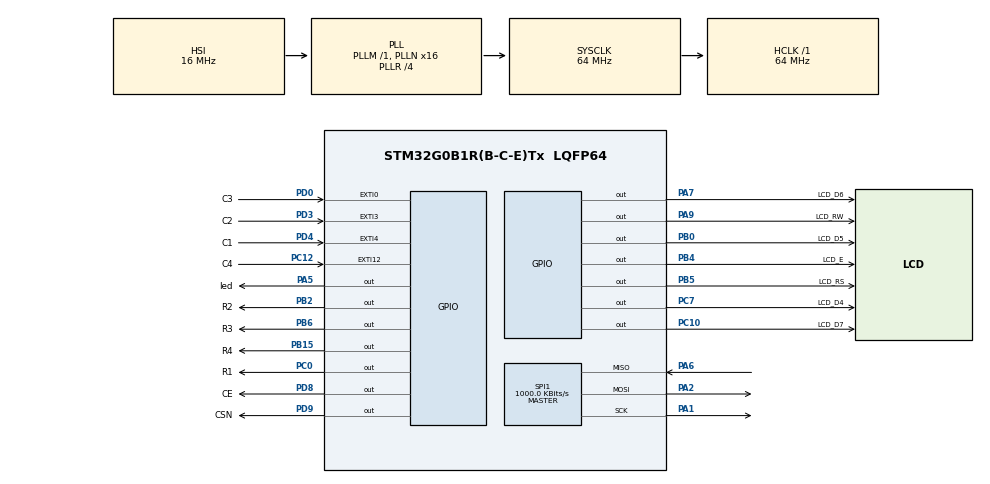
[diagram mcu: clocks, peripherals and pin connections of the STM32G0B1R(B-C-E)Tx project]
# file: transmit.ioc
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Mcu.Family=STM32G0
Mcu.Name=STM32G0B1R(B-C-E)Tx
Mcu.Package=LQFP64
NVIC.EXTI0_1_IRQn=true\:0\:0\:false\:false\:true\:true\:true
NVIC.EXTI2_3_IRQn=true\:0\:0\:false\:false\:true\:true\:true
NVIC.EXTI4_15_IRQn=true\:0\:0\:false\:false\:true\:true\:true
NVIC.SPI1_IRQn=true\:0\:0\:false\:false\:true\:true\:true
NVIC.TIM1_BRK_UP_TRG_COM_IRQn=true\:0\:0\:false\:false\:true\:true\:true
NVIC.TIM1_CC_IRQn=true\:0\:0\:false\:false\:true\:true\:true
PA1.Mode=Full_Duplex_Master
PA1.Signal=SPI1_SCK
PA13.Mode=Serial_Wire
PA13.Signal=SYS_SWDIO
PA14-BOOT0.Mode=Serial_Wire
PA14-BOOT0.Signal=SYS_SWCLK
PA2.Mode=Full_Duplex_Master
PA2.Signal=SPI1_MOSI
PA5.GPIO_Label=led
PA5.Signal=GPIO_Output
PA6.Mode=Full_Duplex_Master
PA6.Signal=SPI1_MISO
PA7.GPIO_Label=LCD_D6
PA7.GPIO_Speed=GPIO_SPEED_FREQ_VERY_HIGH
PA7.Signal=GPIO_Output
PA9.GPIO_FMPA9=__NULL
PA9.GPIO_Label=LCD_RW
PA9.GPIO_Speed=GPIO_SPEED_FREQ_VERY_HIGH
PA9.PinState=GPIO_PIN_RESET
PA9.Signal=GPIO_Output
PB0.GPIO_Label=LCD_D5
PB0.GPIO_Speed=GPIO_SPEED_FREQ_VERY_HIGH
PB0.PinState=GPIO_PIN_RESET
PB0.Signal=GPIO_Output
PB15.GPIO_Label=R4
PB15.PinState=GPIO_PIN_SET
PB15.Signal=GPIO_Output
PB2.GPIO_Label=R2
PB2.PinState=GPIO_PIN_SET
PB2.Signal=GPIO_Output
PB4.GPIO_Label=LCD_E
PB4.GPIO_Speed=GPIO_SPEED_FREQ_VERY_HIGH
PB4.Signal=GPIO_Output
PB5.GPIO_Label=LCD_RS
PB5.GPIO_Speed=GPIO_SPEED_FREQ_VERY_HIGH
PB5.Signal=GPIO_Output
PB6.GPIO_Label=R3
PB6.PinState=GPIO_PIN_SET
PB6.Signal=GPIO_Output
PC0.GPIO_Label=R1
PC0.GPIO_Speed=GPIO_SPEED_FREQ_LOW
PC0.PinState=GPIO_PIN_SET
PC0.Signal=GPIO_Output
PC10.GPIO_Label=LCD_D7
PC10.GPIO_Speed=GPIO_SPEED_FREQ_VERY_HIGH
PC10.Signal=GPIO_Output
PC12.GPIO_Label=C4
PC12.GPIO_ModeDefaultEXTI=GPIO_MODE_IT_FALLING
PC12.GPIO_PuPd=GPIO_PULLUP
PC12.Signal=GPXTI12
PC7.GPIO_Label=LCD_D4
PC7.GPIO_Speed=GPIO_SPEED_FREQ_VERY_HIGH
PC7.Signal=GPIO_Output
PD0.GPIO_Label=C3
PD0.GPIO_ModeDefaultEXTI=GPIO_MODE_IT_FALLING
PD0.GPIO_PuPd=GPIO_PULLUP
PD0.Signal=GPXTI0
PD3.GPIO_Label=C2
PD3.GPIO_ModeDefaultEXTI=GPIO_MODE_IT_FALLING
PD3.GPIO_PuPd=GPIO_PULLUP
PD3.Signal=GPXTI3
PD4.GPIO_Label=C1
PD4.GPIO_ModeDefaultEXTI=GPIO_MODE_IT_FALLING
PD4.GPIO_PuPd=GPIO_PULLUP
PD4.Signal=GPXTI4
PD8.GPIO_Label=CE
PD8.GPIO_Speed=GPIO_SPEED_FREQ_VERY_HIGH
PD8.PinState=GPIO_PIN_SET
PD8.Signal=GPIO_Output
PD9.GPIO_Label=CSN
PD9.GPIO_Speed=GPIO_SPEED_FREQ_VERY_HIGH
PD9.Signal=GPIO_Output
ProjectManager.HeapSize=0x200
ProjectManager.StackSize=0x400
ProjectManager.TargetToolchain=STM32CubeIDE
RCC.ADCFreq_Value=64000000
RCC.AHBFreq_Value=64000000
RCC.CortexFreq_Value=64000000
RCC.EXTERNAL_CLOCK_VALUE=48000
RCC.HCLKFreq_Value=64000000
RCC.HSE_VALUE=8000000
RCC.HSI48_VALUE=48000000
RCC.HSI_VALUE=16000000
RCC.LSE_VALUE=32768
RCC.PLLN=16
RCC.PLLR=RCC_PLLR_DIV4
RCC.SYSCLKFreq_VALUE=64000000
RCC.SYSCLKSource=RCC_SYSCLKSOURCE_PLLCLK
RCC.USBFreq_Value=48000000
RCC.VCOOutputFreq_Value=256000000
SPI1.BaudRatePrescaler=SPI_BAUDRATEPRESCALER_64
SPI1.CalculateBaudRate=1000.0 KBits/s
SPI1.Direction=SPI_DIRECTION_2LINES
SPI1.Mode=SPI_MODE_MASTER
SPI1.VirtualType=VM_MASTER
TIM1.Period=0xffff-1
TIM1.Prescaler=64-1
VP_SYS_VS_DBSignals.Mode=DisableDeadBatterySignals
VP_TIM1_VS_ClockSourceINT.Mode=Internal
board=custom

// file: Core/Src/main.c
/* USER CODE BEGIN Header */
/**
  ******************************************************************************
  * @file           : main.c
  * @brief          : Main program body
  ******************************************************************************
  * @attention
  *
  * Copyright (c) 2022 STMicroelectronics.
  * All rights reserved.
  *
  * This software is licensed under terms that can be found in the LICENSE file
  * in the root directory of this software component.
  * If no LICENSE file comes with this software, it is provided AS-IS.
  *
  ******************************************************************************
  */
/* USER CODE END Header */
#include "main.h"

/* USER CODE BEGIN Includes */

#include "App.h"

/* USER CODE END Includes */

SPI_HandleTypeDef hspi1;

TIM_HandleTypeDef htim1;

void SystemClock_Config(void);
static void MX_GPIO_Init(void);
static void MX_SPI1_Init(void);
static void MX_TIM1_Init(void);

int main(void)
{

  /* MCU Configuration--------------------------------------------------------*/

  /* Reset of all peripherals, Initializes the Flash interface and the Systick. */
   HAL_Init();

  /* Configure the system clock */
  SystemClock_Config();

  /* Initialize all configured peripherals */
  MX_GPIO_Init();
  MX_SPI1_Init();
  MX_TIM1_Init();
  /* USER CODE BEGIN 2 */

  	 app_init();
  	 app_run();

  /* USER CODE END 2 */

  /* Infinite loop */
  while (1)
  {

  }
}

void SystemClock_Config(void)
{
  RCC_OscInitTypeDef RCC_OscInitStruct = {0};
  RCC_ClkInitTypeDef RCC_ClkInitStruct = {0};

  /** Configure the main internal regulator output voltage
  */
  HAL_PWREx_ControlVoltageScaling(PWR_REGULATOR_VOLTAGE_SCALE1);
  /** Initializes the RCC Oscillators according to the specified parameters
  * in the RCC_OscInitTypeDef structure.
  */
  RCC_OscInitStruct.OscillatorType = RCC_OSCILLATORTYPE_HSI;
  RCC_OscInitStruct.HSIState = RCC_HSI_ON;
  RCC_OscInitStruct.HSIDiv = RCC_HSI_DIV1;
  RCC_OscInitStruct.HSICalibrationValue = RCC_HSICALIBRATION_DEFAULT;
  RCC_OscInitStruct.PLL.PLLState = RCC_PLL_ON;
  RCC_OscInitStruct.PLL.PLLSource = RCC_PLLSOURCE_HSI;
  RCC_OscInitStruct.PLL.PLLM = RCC_PLLM_DIV1;
  RCC_OscInitStruct.PLL.PLLN = 16;
  RCC_OscInitStruct.PLL.PLLP = RCC_PLLP_DIV2;
  RCC_OscInitStruct.PLL.PLLQ = RCC_PLLQ_DIV2;
  RCC_OscInitStruct.PLL.PLLR = RCC_PLLR_DIV4;
  if (HAL_RCC_OscConfig(&RCC_OscInitStruct) != HAL_OK)
  {
    Error_Handler();
  }
  /** Initializes the CPU, AHB and APB buses clocks
  */
  RCC_ClkInitStruct.ClockType = RCC_CLOCKTYPE_HCLK|RCC_CLOCKTYPE_SYSCLK
                              |RCC_CLOCKTYPE_PCLK1;
  RCC_ClkInitStruct.SYSCLKSource = RCC_SYSCLKSOURCE_PLLCLK;
  RCC_ClkInitStruct.AHBCLKDivider = RCC_SYSCLK_DIV1;
  RCC_ClkInitStruct.APB1CLKDivider = RCC_HCLK_DIV1;

  if (HAL_RCC_ClockConfig(&RCC_ClkInitStruct, FLASH_LATENCY_2) != HAL_OK)
  {
    Error_Handler();
  }
}

static void MX_SPI1_Init(void)
{

  /* SPI1 parameter configuration*/
  hspi1.Instance = SPI1;
  hspi1.Init.Mode = SPI_MODE_MASTER;
  hspi1.Init.Direction = SPI_DIRECTION_2LINES;
  hspi1.Init.DataSize = SPI_DATASIZE_8BIT;
  hspi1.Init.CLKPolarity = SPI_POLARITY_LOW;
  hspi1.Init.CLKPhase = SPI_PHASE_1EDGE;
  hspi1.Init.NSS = SPI_NSS_SOFT;
  hspi1.Init.BaudRatePrescaler = SPI_BAUDRATEPRESCALER_64;
  hspi1.Init.FirstBit = SPI_FIRSTBIT_MSB;
  hspi1.Init.TIMode = SPI_TIMODE_DISABLE;
  hspi1.Init.CRCCalculation = SPI_CRCCALCULATION_DISABLE;
  hspi1.Init.CRCPolynomial = 7;
  hspi1.Init.CRCLength = SPI_CRC_LENGTH_DATASIZE;
  hspi1.Init.NSSPMode = SPI_NSS_PULSE_ENABLE;
  if (HAL_SPI_Init(&hspi1) != HAL_OK)
  {
    Error_Handler();
  }

}

static void MX_TIM1_Init(void)
{

  TIM_ClockConfigTypeDef sClockSourceConfig = {0};
  TIM_MasterConfigTypeDef sMasterConfig = {0};

  htim1.Instance = TIM1;
  htim1.Init.Prescaler = 64-1;
  htim1.Init.CounterMode = TIM_COUNTERMODE_UP;
  htim1.Init.Period = 0xffff-1;
  htim1.Init.ClockDivision = TIM_CLOCKDIVISION_DIV1;
  htim1.Init.RepetitionCounter = 0;
  htim1.Init.AutoReloadPreload = TIM_AUTORELOAD_PRELOAD_DISABLE;
  if (HAL_TIM_Base_Init(&htim1) != HAL_OK)
  {
    Error_Handler();
  }
  sClockSourceConfig.ClockSource = TIM_CLOCKSOURCE_INTERNAL;
  if (HAL_TIM_ConfigClockSource(&htim1, &sClockSourceConfig) != HAL_OK)
  {
    Error_Handler();
  }
  sMasterConfig.MasterOutputTrigger = TIM_TRGO_RESET;
  sMasterConfig.MasterOutputTrigger2 = TIM_TRGO2_RESET;
  sMasterConfig.MasterSlaveMode = TIM_MASTERSLAVEMODE_DISABLE;
  if (HAL_TIMEx_MasterConfigSynchronization(&htim1, &sMasterConfig) != HAL_OK)
  {
    Error_Handler();
  }

}

static void MX_GPIO_Init(void)
{
  GPIO_InitTypeDef GPIO_InitStruct = {0};

  /* GPIO Ports Clock Enable */
  __HAL_RCC_GPIOC_CLK_ENABLE();
  __HAL_RCC_GPIOA_CLK_ENABLE();
  __HAL_RCC_GPIOB_CLK_ENABLE();
  __HAL_RCC_GPIOD_CLK_ENABLE();

  /*Configure GPIO pin Output Level */
  HAL_GPIO_WritePin(R1_GPIO_Port, R1_Pin, GPIO_PIN_SET);

  /*Configure GPIO pin Output Level */
  HAL_GPIO_WritePin(GPIOA, led_Pin|LCD_D6_Pin|LCD_RW_Pin, GPIO_PIN_RESET);

  /*Configure GPIO pin Output Level */
  HAL_GPIO_WritePin(GPIOB, LCD_D5_Pin|LCD_E_Pin|LCD_RS_Pin, GPIO_PIN_RESET);

  /*Configure GPIO pin Output Level */
  HAL_GPIO_WritePin(GPIOB, R2_Pin|R4_Pin|R3_Pin, GPIO_PIN_SET);

  /*Configure GPIO pin Output Level */
  HAL_GPIO_WritePin(GPIOC, LCD_D4_Pin|LCD_D7_Pin, GPIO_PIN_RESET);

  /*Configure GPIO pin Output Level */
  HAL_GPIO_WritePin(CE_GPIO_Port, CE_Pin, GPIO_PIN_SET);

  /*Configure GPIO pin Output Level */
  HAL_GPIO_WritePin(CSN_GPIO_Port, CSN_Pin, GPIO_PIN_RESET);

  /*Configure GPIO pin : C4_Pin */
  GPIO_InitStruct.Pin = C4_Pin;
  GPIO_InitStruct.Mode = GPIO_MODE_IT_FALLING;
  GPIO_InitStruct.Pull = GPIO_PULLUP;
  HAL_GPIO_Init(C4_GPIO_Port, &GPIO_InitStruct);

  /*Configure GPIO pin : R1_Pin */
  GPIO_InitStruct.Pin = R1_Pin;
  GPIO_InitStruct.Mode = GPIO_MODE_OUTPUT_PP;
  GPIO_InitStruct.Pull = GPIO_NOPULL;
  GPIO_InitStruct.Speed = GPIO_SPEED_FREQ_LOW;
  HAL_GPIO_Init(R1_GPIO_Port, &GPIO_InitStruct);

  /*Configure GPIO pin : led_Pin */
  GPIO_InitStruct.Pin = led_Pin;
  GPIO_InitStruct.Mode = GPIO_MODE_OUTPUT_PP;
  GPIO_InitStruct.Pull = GPIO_NOPULL;
  GPIO_InitStruct.Speed = GPIO_SPEED_FREQ_LOW;
  HAL_GPIO_Init(led_GPIO_Port, &GPIO_InitStruct);

  /*Configure GPIO pins : LCD_D6_Pin LCD_RW_Pin */
  GPIO_InitStruct.Pin = LCD_D6_Pin|LCD_RW_Pin;
  GPIO_InitStruct.Mode = GPIO_MODE_OUTPUT_PP;
  GPIO_InitStruct.Pull = GPIO_NOPULL;
  GPIO_InitStruct.Speed = GPIO_SPEED_FREQ_VERY_HIGH;
  HAL_GPIO_Init(GPIOA, &GPIO_InitStruct);

  /*Configure GPIO pins : LCD_D5_Pin LCD_E_Pin LCD_RS_Pin */
  GPIO_InitStruct.Pin = LCD_D5_Pin|LCD_E_Pin|LCD_RS_Pin;
  GPIO_InitStruct.Mode = GPIO_MODE_OUTPUT_PP;
  GPIO_InitStruct.Pull = GPIO_NOPULL;
  GPIO_InitStruct.Speed = GPIO_SPEED_FREQ_VERY_HIGH;
  HAL_GPIO_Init(GPIOB, &GPIO_InitStruct);

  /*Configure GPIO pins : R2_Pin R4_Pin R3_Pin */
  GPIO_InitStruct.Pin = R2_Pin|R4_Pin|R3_Pin;
  GPIO_InitStruct.Mode = GPIO_MODE_OUTPUT_PP;
  GPIO_InitStruct.Pull = GPIO_NOPULL;
  GPIO_InitStruct.Speed = GPIO_SPEED_FREQ_LOW;
  HAL_GPIO_Init(GPIOB, &GPIO_InitStruct);

  /*Configure GPIO pins : LCD_D4_Pin LCD_D7_Pin */
  GPIO_InitStruct.Pin = LCD_D4_Pin|LCD_D7_Pin;
  GPIO_InitStruct.Mode = GPIO_MODE_OUTPUT_PP;
  GPIO_InitStruct.Pull = GPIO_NOPULL;
  GPIO_InitStruct.Speed = GPIO_SPEED_FREQ_VERY_HIGH;
  HAL_GPIO_Init(GPIOC, &GPIO_InitStruct);

  /*Configure GPIO pins : CE_Pin CSN_Pin */
  GPIO_InitStruct.Pin = CE_Pin|CSN_Pin;
  GPIO_InitStruct.Mode = GPIO_MODE_OUTPUT_PP;
  GPIO_InitStruct.Pull = GPIO_NOPULL;
  GPIO_InitStruct.Speed = GPIO_SPEED_FREQ_VERY_HIGH;
  HAL_GPIO_Init(GPIOD, &GPIO_InitStruct);

  /*Configure GPIO pins : C3_Pin C2_Pin C1_Pin */
  GPIO_InitStruct.Pin = C3_Pin|C2_Pin|C1_Pin;
  GPIO_InitStruct.Mode = GPIO_MODE_IT_FALLING;
  GPIO_InitStruct.Pull = GPIO_PULLUP;
  HAL_GPIO_Init(GPIOD, &GPIO_InitStruct);

  /* EXTI interrupt init*/
  HAL_NVIC_SetPriority(EXTI0_1_IRQn, 0, 0);
  HAL_NVIC_EnableIRQ(EXTI0_1_IRQn);

  HAL_NVIC_SetPriority(EXTI2_3_IRQn, 0, 0);
  HAL_NVIC_EnableIRQ(EXTI2_3_IRQn);

  HAL_NVIC_SetPriority(EXTI4_15_IRQn, 0, 0);
  HAL_NVIC_EnableIRQ(EXTI4_15_IRQn);

}

void Error_Handler(void)
{
  __disable_irq();
  while (1)
  {
  }
}
